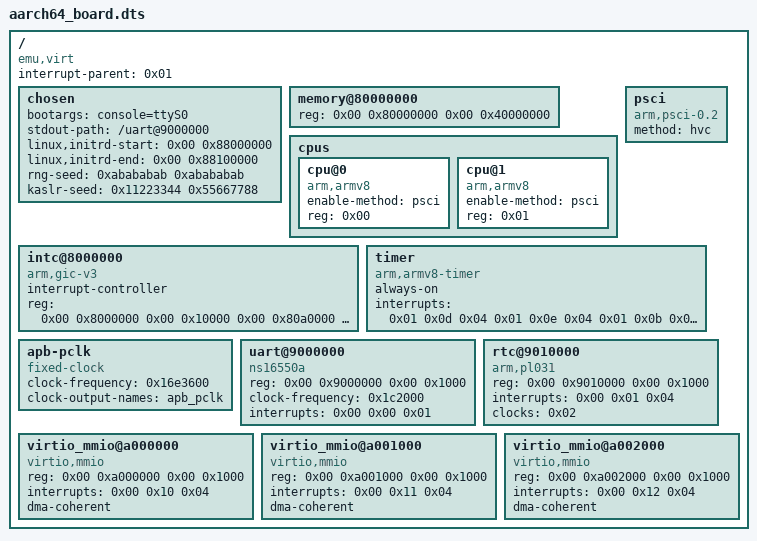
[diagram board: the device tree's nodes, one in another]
/dts-v1/;

/ {
	compatible = "emu,virt";
	#address-cells = <0x02>;
	#size-cells = <0x02>;
	interrupt-parent = <0x01>;

	chosen {
		bootargs = "console=ttyS0";
		stdout-path = "/uart@9000000";
		linux,initrd-start = <0x00 0x88000000>;
		linux,initrd-end = <0x00 0x88100000>;
		rng-seed = <0xabababab 0xabababab>;
		kaslr-seed = <0x11223344 0x55667788>;
	};

	memory@80000000 {
		device_type = "memory";
		reg = <0x00 0x80000000 0x00 0x40000000>;
	};

	cpus {
		#address-cells = <0x01>;
		#size-cells = <0x00>;

		cpu@0 {
			device_type = "cpu";
			compatible = "arm,armv8";
			enable-method = "psci";
			reg = <0x00>;
		};

		cpu@1 {
			device_type = "cpu";
			compatible = "arm,armv8";
			enable-method = "psci";
			reg = <0x01>;
		};
	};

	psci {
		compatible = "arm,psci-0.2";
		method = "hvc";
	};

	intc@8000000 {
		compatible = "arm,gic-v3";
		interrupt-controller;
		#interrupt-cells = <0x03>;
		reg = <0x00 0x8000000 0x00 0x10000 0x00 0x80a0000 0x00 0x40000>;
		phandle = <0x01>;
	};

	timer {
		compatible = "arm,armv8-timer";
		always-on;
		interrupts = <0x01 0x0d 0x04 0x01 0x0e 0x04 0x01 0x0b 0x04 0x01 0x0a 0x04>;
	};

	apb-pclk {
		compatible = "fixed-clock";
		#clock-cells = <0x00>;
		clock-frequency = <0x16e3600>;
		clock-output-names = "apb_pclk";
		phandle = <0x02>;
	};

	uart@9000000 {
		compatible = "ns16550a";
		reg = <0x00 0x9000000 0x00 0x1000>;
		clock-frequency = <0x1c2000>;
		interrupts = <0x00 0x00 0x01>;
	};

	rtc@9010000 {
		compatible = "arm,pl031", "arm,primecell";
		reg = <0x00 0x9010000 0x00 0x1000>;
		interrupts = <0x00 0x01 0x04>;
		clocks = <0x02>;
		clock-names = "apb_pclk";
	};

	virtio_mmio@a000000 {
		compatible = "virtio,mmio";
		reg = <0x00 0xa000000 0x00 0x1000>;
		interrupts = <0x00 0x10 0x04>;
		dma-coherent;
	};

	virtio_mmio@a001000 {
		compatible = "virtio,mmio";
		reg = <0x00 0xa001000 0x00 0x1000>;
		interrupts = <0x00 0x11 0x04>;
		dma-coherent;
	};

	virtio_mmio@a002000 {
		compatible = "virtio,mmio";
		reg = <0x00 0xa002000 0x00 0x1000>;
		interrupts = <0x00 0x12 0x04>;
		dma-coherent;
	};
};
